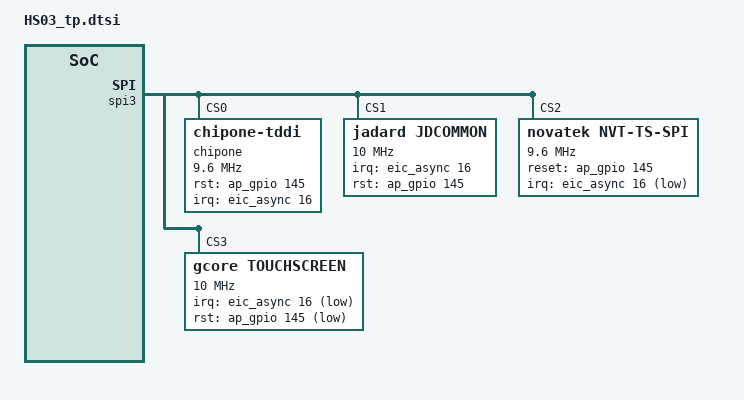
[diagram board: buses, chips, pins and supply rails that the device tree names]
&spi3 {
	status = "okay";
	cs-gpios = <0>, <0>, <0>, <0>;

	/*HS03 code for SR-SL6215-01-98|SR-SL6215-01-761|SR-SL6215-01-787  by zhoulingyun at 20211213 start*/
	/* chipone device tree node */
	chipone@0 {
		compatible = "chipone-tddi";
		reg = <0>; //Same as CS ID
		status = "ok";

		spi-max-frequency = <9600000>;	//4800000,9600000,15000000,19200000

		/*icnl9911c ===========start===========*/
		interrupt-parent = <&ap_gpio>;
		//interrupts = <144 0x2000>;
		chipone,rst-gpio = <&ap_gpio 145 GPIO_ACTIVE_HIGH>;
		/*HS03 code for P211028-04422  by chenyihong at 20211028 start*/
		chipone,irq-gpio = <&eic_async 16 GPIO_ACTIVE_HIGH>;
		/*HS03 code for P211028-04422  by chenyihong at 20211028 end*/
		touch,max-touch-number = <5>;
		touch,display-coords =  <0 0 720 1600>;
		chipone,x-res = <720>;
		chipone,y-res = <1600>;

		/* selftest settings */
		//selftest start
		chipone_hlt_hsd,test-reset-pin;
		//chipone_hlt_hsd,test-int-pin;
		chipone_hlt_hsd,test-rawdata;
		chipone_hlt_hsd,test-rawdata-frames = <1>;
		chipone_hlt_hsd,rawdata-min = <1430>;
		chipone_hlt_hsd,rawdata-max = <2970>;
		chipone_hlt_hsd,test-noise;
		chipone_hlt_hsd,test-noise-frames = <50>;
		chipone_hlt_hsd,noise-max = <76>;
		chipone_hlt_hsd,test-open;
		chipone_hlt_hsd,open-min = <3120>;
		chipone_hlt_hsd,test-short;
		chipone_hlt_hsd,short-min = <500>;
		chipone_hlt_hsd,test-compensate-cap;
		chipone_hlt_hsd,compensate-cap-min = <1>;
		chipone_hlt_hsd,compensate-cap-max = <126>;
		//selftest end

		/* selftest settings */
		//selftest start
		chipone_genrpro_inx,test-reset-pin;
		//chipone_genrpro_inx,test-int-pin;

		chipone_genrpro_inx,test-rawdata;
		chipone_genrpro_inx,test-rawdata-frames = <1>;
		chipone_genrpro_inx,rawdata-min = <1610>;//RAW_DEST_VALUE 2300*70%
		chipone_genrpro_inx,rawdata-max = <2990>;//RAW_DEST_VALUE 2300*130%

		chipone_genrpro_inx,test-noise;
		chipone_genrpro_inx,test-noise-frames = <50>;
		chipone_genrpro_inx,noise-max = <59>;//TCH_DOWN_TH_5PT 65*90% 

		chipone_genrpro_inx,test-open;
		chipone_genrpro_inx,open-min = <3466>;//SCAN_FREQ 97 /CYCLE_NUM 10 /SHIFT_NUM 7

		chipone_genrpro_inx,test-short;
		chipone_genrpro_inx,short-min = <500>;//default

		chipone_genrpro_inx,test-compensate-cap;
		chipone_genrpro_inx,compensate-cap-min = <1>;
		chipone_genrpro_inx,compensate-cap-max = <126>;
		//selftest end

		/* selftest settings */
		//selftest start
		chipone_tm,test-reset-pin;
		//chipone_tm,test-int-pin;

		chipone_tm,test-rawdata;
		chipone_tm,test-rawdata-frames = <1>;
		chipone_tm,rawdata-min = <1540>;
		chipone_tm,rawdata-max = <2860>;

		chipone_tm,test-noise;
		chipone_tm,test-noise-frames = <50>;
		chipone_tm,noise-max = <60>;

		chipone_tm,test-open;
		chipone_tm,open-min = <3100>;

		chipone_tm,test-short;
		chipone_tm,short-min = <500>;

		chipone_tm,test-compensate-cap;
		chipone_tm,compensate-cap-min = <1>;
		chipone_tm,compensate-cap-max = <126>;
		//selftest end

		/* selftest settings */
		//selftest start
		chipone_genrpro,test-reset-pin;
		//chipone_genrpro,test-int-pin;

		chipone_genrpro,test-rawdata;
		chipone_genrpro,test-rawdata-frames = <1>;
		chipone_genrpro,rawdata-min = <1610>;//base 2300*30%
		chipone_genrpro,rawdata-max = <2990>;

		chipone_genrpro,test-noise;
		chipone_genrpro,test-noise-frames = <50>;
		chipone_genrpro,noise-max = <70>;

		chipone_genrpro,test-open;
		chipone_genrpro,open-min = <3000>;

		chipone_genrpro,test-short;
		chipone_genrpro,short-min = <500>;

		chipone_genrpro,test-compensate-cap;
		chipone_genrpro,compensate-cap-min = <1>;
		chipone_genrpro,compensate-cap-max = <126>;
		//selftest end

		/* selftest settings */
		//selftest start
		chipone_truly_6mask,test-reset-pin;
		//chipone_truly_6mask,test-int-pin;

		chipone_truly_6mask,test-rawdata;
		chipone_truly_6mask,test-rawdata-frames = <1>;
		chipone_truly_6mask,rawdata-min = <1320>;//base 2200*40%
		chipone_truly_6mask,rawdata-max = <3080>;

		chipone_truly_6mask,test-noise;
		chipone_truly_6mask,test-noise-frames = <50>;
		chipone_truly_6mask,noise-max = <80>;

		chipone_truly_6mask,test-open;
		chipone_truly_6mask,open-min = <2700>;

		chipone_truly_6mask,test-short;
		chipone_truly_6mask,short-min = <500>;

		chipone_truly_6mask,test-compensate-cap;
		chipone_truly_6mask,compensate-cap-min = <1>;
		chipone_truly_6mask,compensate-cap-max = <126>;
		//selftest end

		/* selftest settings */
		//selftest start
		chipone_truly_7mask,test-reset-pin;
		//chipone_truly_7mask,test-int-pin;

		chipone_truly_7mask,test-rawdata;
		chipone_truly_7mask,test-rawdata-frames = <1>;
		chipone_truly_7mask,rawdata-min = <1320>;//base 2200*40%
		chipone_truly_7mask,rawdata-max = <3080>;

		chipone_truly_7mask,test-noise;
		chipone_truly_7mask,test-noise-frames = <50>;
		chipone_truly_7mask,noise-max = <80>;

		chipone_truly_7mask,test-open;
		chipone_truly_7mask,open-min = <2700>;

		chipone_truly_7mask,test-short;
		chipone_truly_7mask,short-min = <500>;

		chipone_truly_7mask,test-compensate-cap;
		chipone_truly_7mask,compensate-cap-min = <1>;
		chipone_truly_7mask,compensate-cap-max = <126>;
		//selftest end

		/* Charger detect */
		chipone,touch-charger-detect-enable;
		chipone,touch-charger-detect-type = "notify"; /* notify, poll */
		chipone,touch-charger-detect-psy-name = "usb";
		chipone,touch-charger-detect-psp = "POWER_SUPPLY_PROP_ONLINE";
		chipone,touch-charger-detect-psp-poll-interval = <1000>;

		/* Earjack detect */
		chipone,touch-earjack-detect-enable;
		/* MTK:  /sys/bus/platform/drivers/Accdet_Driver/state,
		Sprd: /sys/kernel/headset/state
		QCOM: None, and disable it */
		chipone,touch-earjack-state-filepath = "/sys/kernel/headset/state";
		chipone,touch-earjack-poll-interval = <1000>;
		/*icnl9911c ===========end===========*/
	};
	/*HS03 code for SR-SL6215-01-98|SR-SL6215-01-761|SR-SL6215-01-787  by zhoulingyun at 20211213 end*/

	/*HS03 code for SR-SL6215-01-108 by chenyihong at 20210729 start*/
	jadard@1 {
		compatible = "jadard,jdcommon";
		reg = <1>;
		spi-max-frequency = <10000000>;
		interrupt-parent = <&ap_gpio>;
		//interrupts = <144 0x2002>;
		jadard,panel-sense-nums = <18 32>;
		jadard,panel-coords = <0 720 0 1600>;
		jadard,panel-max-points = <10>;
		jadard,int-is-edge = <1>;
		/*HS03 code for P211028-04422  by chenyihong at 20211028 start*/
		jadard,irq-gpio = <&eic_async 16 GPIO_ACTIVE_HIGH>;
		/*HS03 code for P211028-04422  by chenyihong at 20211028 end*/
		jadard,rst-gpio = <&ap_gpio 145 GPIO_ACTIVE_HIGH>;
	};
	/*HS03 code for SR-SL6215-01-108 by chenyihong at 20210729 end*/

	/*HS03 code for SR-SL6215-01-102|SL6215DEV-3496 by zhoulingyun at 20211105 start*/
	/* Novatek device tree node */
	novatek@2 {
		compatible = "novatek,NVT-ts-spi";
		reg = <2>; //Same as CS ID
		status = "ok";

		interrupt-parent = <&ap_gpio>;
		//interrupts = <144 0x2001>;
		spi-max-frequency = <9600000>;	//4800000,9600000,15000000,19200000
		novatek,reset-gpio = <&ap_gpio 145 0x00>;
		/*HS03 code for P211028-04422  by chenyihong at 20211028 start*/
		novatek,irq-gpio = <&eic_async 16 0x2001>;
		/*HS03 code for P211028-04422  by chenyihong at 20211028 end*/

		/* 525 */
		//novatek,swrst-n8-addr = <0x01F01A>;

		/* 672A, 525B, 675, 526, 672C */
		novatek,swrst-n8-addr = <0x03F0FE>;
		novatek,spi-rd-fast-addr = <0x03F310>;

		/*Panel setting*/
		novatek,resolution = <720 1600>;
		novatek,max_touch_num = <10>;
		novatek,area-size = <56 112 60>;	//indicator navigation edge
		novatek,fw_name = "novatek_ts_fw.bin", "tsp_novatek/nt36525_a01core_tp.bin";
		novatek,fw_name_mp = "novatek_ts_mp.bin", "tsp_novatek/nt36525_a01core_mp.bin";
		novatek,support_ear_detect_mode;
		novatek,enable_settings_aot;

		/* MP */
		novatek,mp-support-dt;

		novatek-mp-criteria-7237@0 {
			#address-cells = <1>;
			#size-cells = <0>;
			compatible = "novatek-mp-criteria-7237";

			/* sec cmd test config */
			open_test_spec = <(-511) 5120>;
			short_test_spec = <10000 14008>;
			diff_test_frame = <50>;
			/* sec cmd fdm test config */
			fdm_x_num = <2>;
			fdm_diff_test_frame = <50>;

			/* MP Config */
			IC_X_CFG_SIZE = <18>;
			IC_Y_CFG_SIZE = <32>;
			IC_KEY_CFG_SIZE = <4>;
			X_Channel = <18>;
			Y_Channel = <32>;
			AIN_X = <0 1 2 3 4 5 6 7 8 9 10 11 12 13 14 15 16 17>;
			AIN_Y = <0 1 2 3 4 5 6 7 8 9 10 11 12 13 14 15 16 17
						18 19 20 21 22 23 24 25 26 27 28 29 30 31>;
			AIN_KEY = <0 1 2 0xFF>;
			/*HS03 code for SL6215DEV-189 by zhoulingyun at 20210818 start*/
			/* MP Criteria */
			PS_Config_Lmt_Short_Rawdata_P = <
				14008	14008	14008	14008	14008	14008	14008	14008	14008	14008	14008	14008	14008	14008	14008	14008	14008	14008
				14008	14008	14008	14008	14008	14008	14008	14008	14008	14008	14008	14008	14008	14008	14008	14008	14008	14008
				14008	14008	14008	14008	14008	14008	14008	14008	14008	14008	14008	14008	14008	14008	14008	14008	14008	14008
				14008	14008	14008	14008	14008	14008	14008	14008	14008	14008	14008	14008	14008	14008	14008	14008	14008	14008
				14008	14008	14008	14008	14008	14008	14008	14008	14008	14008	14008	14008	14008	14008	14008	14008	14008	14008
				14008	14008	14008	14008	14008	14008	14008	14008	14008	14008	14008	14008	14008	14008	14008	14008	14008	14008
				14008	14008	14008	14008	14008	14008	14008	14008	14008	14008	14008	14008	14008	14008	14008	14008	14008	14008
				14008	14008	14008	14008	14008	14008	14008	14008	14008	14008	14008	14008	14008	14008	14008	14008	14008	14008
				14008	14008	14008	14008	14008	14008	14008	14008	14008	14008	14008	14008	14008	14008	14008	14008	14008	14008
				14008	14008	14008	14008	14008	14008	14008	14008	14008	14008	14008	14008	14008	14008	14008	14008	14008	14008
				14008	14008	14008	14008	14008	14008	14008	14008	14008	14008	14008	14008	14008	14008	14008	14008	14008	14008
				14008	14008	14008	14008	14008	14008	14008	14008	14008	14008	14008	14008	14008	14008	14008	14008	14008	14008
				14008	14008	14008	14008	14008	14008	14008	14008	14008	14008	14008	14008	14008	14008	14008	14008	14008	14008
				14008	14008	14008	14008	14008	14008	14008	14008	14008	14008	14008	14008	14008	14008	14008	14008	14008	14008
				14008	14008	14008	14008	14008	14008	14008	14008	14008	14008	14008	14008	14008	14008	14008	14008	14008	14008
				14008	14008	14008	14008	14008	14008	14008	14008	14008	14008	14008	14008	14008	14008	14008	14008	14008	14008
				14008	14008	14008	14008	14008	14008	14008	14008	14008	14008	14008	14008	14008	14008	14008	14008	14008	14008
				14008	14008	14008	14008	14008	14008	14008	14008	14008	14008	14008	14008	14008	14008	14008	14008	14008	14008
				14008	14008	14008	14008	14008	14008	14008	14008	14008	14008	14008	14008	14008	14008	14008	14008	14008	14008
				14008	14008	14008	14008	14008	14008	14008	14008	14008	14008	14008	14008	14008	14008	14008	14008	14008	14008
				14008	14008	14008	14008	14008	14008	14008	14008	14008	14008	14008	14008	14008	14008	14008	14008	14008	14008
				14008	14008	14008	14008	14008	14008	14008	14008	14008	14008	14008	14008	14008	14008	14008	14008	14008	14008
				14008	14008	14008	14008	14008	14008	14008	14008	14008	14008	14008	14008	14008	14008	14008	14008	14008	14008
				14008	14008	14008	14008	14008	14008	14008	14008	14008	14008	14008	14008	14008	14008	14008	14008	14008	14008
				14008	14008	14008	14008	14008	14008	14008	14008	14008	14008	14008	14008	14008	14008	14008	14008	14008	14008
				14008	14008	14008	14008	14008	14008	14008	14008	14008	14008	14008	14008	14008	14008	14008	14008	14008	14008
				14008	14008	14008	14008	14008	14008	14008	14008	14008	14008	14008	14008	14008	14008	14008	14008	14008	14008
				14008	14008	14008	14008	14008	14008	14008	14008	14008	14008	14008	14008	14008	14008	14008	14008	14008	14008
				14008	14008	14008	14008	14008	14008	14008	14008	14008	14008	14008	14008	14008	14008	14008	14008	14008	14008
				14008	14008	14008	14008	14008	14008	14008	14008	14008	14008	14008	14008	14008	14008	14008	14008	14008	14008
				14008	14008	14008	14008	14008	14008	14008	14008	14008	14008	14008	14008	14008	14008	14008	14008	14008	14008
				14008	14008	14008	14008	14008	14008	14008	14008	14008	14008	14008	14008	14008	14008	14008	14008	14008	14008>;

			PS_Config_Lmt_Short_Rawdata_N = <
				11376	11376	11376	11376	11376	11376	11376	11376	11376	11376	11376	11376	11376	11376	11376	11376	11376	11376
				11376	11376	11376	11376	11376	11376	11376	11376	11376	11376	11376	11376	11376	11376	11376	11376	11376	11376
				11376	11376	11376	11376	11376	11376	11376	11376	11376	11376	11376	11376	11376	11376	11376	11376	11376	11376
				11376	11376	11376	11376	11376	11376	11376	11376	11376	11376	11376	11376	11376	11376	11376	11376	11376	11376
				11376	11376	11376	11376	11376	11376	11376	11376	11376	11376	11376	11376	11376	11376	11376	11376	11376	11376
				11376	11376	11376	11376	11376	11376	11376	11376	11376	11376	11376	11376	11376	11376	11376	11376	11376	11376
				11376	11376	11376	11376	11376	11376	11376	11376	11376	11376	11376	11376	11376	11376	11376	11376	11376	11376
				11376	11376	11376	11376	11376	11376	11376	11376	11376	11376	11376	11376	11376	11376	11376	11376	11376	11376
				11376	11376	11376	11376	11376	11376	11376	11376	11376	11376	11376	11376	11376	11376	11376	11376	11376	11376
				11376	11376	11376	11376	11376	11376	11376	11376	11376	11376	11376	11376	11376	11376	11376	11376	11376	11376
				11376	11376	11376	11376	11376	11376	11376	11376	11376	11376	11376	11376	11376	11376	11376	11376	11376	11376
				11376	11376	11376	11376	11376	11376	11376	11376	11376	11376	11376	11376	11376	11376	11376	11376	11376	11376
				11376	11376	11376	11376	11376	11376	11376	11376	11376	11376	11376	11376	11376	11376	11376	11376	11376	11376
				11376	11376	11376	11376	11376	11376	11376	11376	11376	11376	11376	11376	11376	11376	11376	11376	11376	11376
				11376	11376	11376	11376	11376	11376	11376	11376	11376	11376	11376	11376	11376	11376	11376	11376	11376	11376
				11376	11376	11376	11376	11376	11376	11376	11376	11376	11376	11376	11376	11376	11376	11376	11376	11376	11376
				11376	11376	11376	11376	11376	11376	11376	11376	11376	11376	11376	11376	11376	11376	11376	11376	11376	11376
				11376	11376	11376	11376	11376	11376	11376	11376	11376	11376	11376	11376	11376	11376	11376	11376	11376	11376
				11376	11376	11376	11376	11376	11376	11376	11376	11376	11376	11376	11376	11376	11376	11376	11376	11376	11376
				11376	11376	11376	11376	11376	11376	11376	11376	11376	11376	11376	11376	11376	11376	11376	11376	11376	11376
				11376	11376	11376	11376	11376	11376	11376	11376	11376	11376	11376	11376	11376	11376	11376	11376	11376	11376
				11376	11376	11376	11376	11376	11376	11376	11376	11376	11376	11376	11376	11376	11376	11376	11376	11376	11376
				11376	11376	11376	11376	11376	11376	11376	11376	11376	11376	11376	11376	11376	11376	11376	11376	11376	11376
				11376	11376	11376	11376	11376	11376	11376	11376	11376	11376	11376	11376	11376	11376	11376	11376	11376	11376
				11376	11376	11376	11376	11376	11376	11376	11376	11376	11376	11376	11376	11376	11376	11376	11376	11376	11376
				11376	11376	11376	11376	11376	11376	11376	11376	11376	11376	11376	11376	11376	11376	11376	11376	11376	11376
				11376	11376	11376	11376	11376	11376	11376	11376	11376	11376	11376	11376	11376	11376	11376	11376	11376	11376
				11376	11376	11376	11376	11376	11376	11376	11376	11376	11376	11376	11376	11376	11376	11376	11376	11376	11376
				11376	11376	11376	11376	11376	11376	11376	11376	11376	11376	11376	11376	11376	11376	11376	11376	11376	11376
				11376	11376	11376	11376	11376	11376	11376	11376	11376	11376	11376	11376	11376	11376	11376	11376	11376	11376
				11376	11376	11376	11376	11376	11376	11376	11376	11376	11376	11376	11376	11376	11376	11376	11376	11376	11376
				11376	11376	11376	11376	11376	11376	11376	11376	11376	11376	11376	11376	11376	11376	11376	11376	11376	11376>;

			PS_Config_Lmt_Open_Rawdata_P = <
				3112	3123	3131	3166	3204	3169	3148	3222	3222	3211	3211	3140	3171	3213	3257	3308	3318	3255
				2907	2920	2963	3033	3099	3092	3080	3067	3018	2994	3057	3070	3095	3102	3117	3134	3101	3035
				2989	3005	3047	3123	3199	3196	3172	3165	3105	2994	3054	3073	3092	3105	3117	3140	3108	3056
				2997	3001	3047	3122	3201	3203	3180	3171	3110	3029	3098	3115	3137	3148	3162	3183	3158	3116
				3026	3035	3081	3158	3238	3232	3210	3200	3138	3033	3103	3122	3140	3155	3166	3186	3169	3127
				3011	3017	3061	3138	3218	3234	3211	3201	3133	3102	3179	3194	3215	3235	3246	3266	3253	3207
				3140	3151	3182	3193	3193	3183	3192	3175	3143	3270	3288	3311	3299	3290	3199	3105	3039	2989
				3140	3148	3180	3197	3190	3190	3186	3178	3140	3264	3287	3301	3304	3304	3222	3119	3053	3003
				3175	3189	3227	3249	3239	3232	3220	3213	3176	3330	3357	3371	3385	3386	3302	3197	3134	3084
				3214	3232	3281	3299	3298	3298	3287	3269	3232	3392	3418	3442	3449	3456	3367	3263	3197	3140
				3273	3287	3337	3354	3340	3330	3316	3299	3271	3372	3396	3420	3432	3446	3374	3269	3203	3148
				3311	3329	3388	3407	3402	3392	3369	3351	3325	3463	3488	3509	3536	3549	3476	3368	3299	3243
				3313	3329	3417	3428	3425	3414	3396	3381	3364	3427	3449	3465	3493	3505	3435	3336	3248	3190
				3337	3358	3439	3463	3448	3444	3423	3407	3388	3480	3502	3518	3543	3556	3504	3402	3315	3253
				3389	3413	3490	3508	3497	3479	3470	3459	3431	3528	3554	3572	3582	3610	3554	3466	3378	3318
				3452	3472	3546	3572	3549	3537	3511	3498	3467	3600	3628	3647	3665	3683	3644	3551	3463	3399
				3462	3476	3550	3568	3558	3550	3529	3514	3484	3560	3585	3605	3631	3649	3612	3533	3444	3378
				3529	3553	3624	3645	3637	3626	3603	3589	3557	3609	3638	3665	3684	3704	3672	3599	3512	3449
				3561	3574	3647	3651	3649	3637	3620	3596	3565	3637	3673	3696	3724	3739	3714	3644	3565	3494
				3607	3628	3701	3721	3717	3703	3689	3669	3638	3665	3703	3721	3745	3763	3749	3677	3605	3540
				3628	3633	3698	3725	3712	3700	3682	3659	3623	3704	3742	3763	3789	3806	3798	3722	3656	3598
				3701	3710	3782	3817	3809	3801	3784	3761	3722	3725	3767	3791	3816	3833	3838	3768	3693	3633
				3774	3778	3833	3901	3901	3887	3862	3843	3798	3778	3826	3847	3873	3889	3911	3873	3815	3756
				3801	3799	3852	3913	3917	3904	3880	3858	3815	3805	3852	3876	3901	3915	3936	3915	3857	3805
				3822	3819	3871	3929	3945	3934	3918	3896	3850	3757	3805	3822	3845	3858	3875	3865	3809	3771
				3851	3841	3887	3939	3955	3945	3924	3903	3858	3872	3917	3936	3960	3976	3994	3990	3938	3900
				3691	3885	3925	3980	3998	3988	3992	3974	3935	3873	3917	3935	3935	3957	3971	3969	3928	3683
				3696	3890	3931	3969	3990	3981	3985	3969	3929	3922	3969	3987	3988	4009	4022	4034	3995	3731
				3750	3956	3992	4033	4054	4047	4044	4034	3991	3896	3943	3957	3963	3981	3998	4012	3978	3718
				3732	3936	3974	4004	4029	4025	4023	4009	3967	4013	4058	4071	4076	4090	4111	4138	4104	3824
				3799	4016	4048	4072	4096	4088	4089	4072	4033	3932	3974	3988	3994	4011	4026	4060	4036	3766
				3869	3936	4051	4069	4095	4088	4089	4071	4030	3998	4043	4053	4060	4076	4097	4131	4019	3897>;

			PS_Config_Lmt_Open_Rawdata_N = <
				1333	1338	1342	1357	1373	1358	1349	1381	1381	1376	1376	1345	1359	1377	1396	1417	1422	1395
				1246	1251	1270	1300	1328	1325	1320	1314	1293	1283	1310	1315	1326	1329	1336	1343	1329	1300
				1281	1288	1306	1338	1371	1369	1359	1356	1330	1283	1309	1317	1325	1330	1336	1345	1332	1309
				1284	1286	1306	1338	1372	1372	1363	1359	1333	1298	1327	1335	1344	1349	1355	1364	1353	1335
				1297	1300	1320	1353	1387	1385	1375	1371	1345	1300	1330	1338	1345	1352	1357	1365	1358	1340
				1290	1293	1312	1345	1379	1386	1376	1372	1342	1329	1362	1369	1378	1386	1391	1399	1394	1374
				1345	1350	1363	1368	1368	1364	1368	1360	1347	1401	1409	1419	1414	1410	1371	1330	1302	1281
				1345	1349	1363	1370	1367	1367	1365	1362	1345	1399	1408	1414	1416	1416	1381	1336	1308	1287
				1360	1366	1383	1392	1388	1385	1380	1377	1361	1427	1438	1444	1450	1451	1415	1370	1343	1321
				1377	1385	1406	1414	1413	1413	1408	1401	1385	1453	1465	1475	1478	1481	1443	1398	1370	1345
				1402	1408	1430	1437	1431	1427	1421	1414	1402	1445	1455	1465	1471	1477	1446	1401	1372	1349
				1419	1426	1452	1460	1458	1453	1444	1436	1425	1484	1495	1504	1515	1521	1489	1443	1414	1390
				1420	1426	1464	1469	1468	1463	1455	1449	1441	1468	1478	1485	1497	1502	1472	1429	1392	1367
				1430	1439	1474	1484	1477	1476	1467	1460	1452	1491	1501	1507	1518	1524	1501	1458	1420	1394
				1452	1462	1495	1503	1498	1491	1487	1482	1470	1512	1523	1531	1535	1547	1523	1485	1447	1422
				1479	1488	1519	1531	1521	1516	1504	1499	1486	1543	1555	1563	1570	1578	1561	1522	1484	1456
				1483	1489	1521	1529	1525	1521	1512	1506	1493	1525	1536	1545	1556	1564	1548	1514	1476	1447
				1512	1522	1553	1562	1558	1554	1544	1538	1524	1546	1559	1570	1579	1587	1573	1542	1505	1478
				1526	1531	1563	1564	1564	1558	1551	1541	1528	1558	1574	1584	1596	1602	1591	1561	1528	1497
				1546	1555	1586	1594	1593	1587	1581	1572	1559	1570	1587	1594	1605	1612	1606	1576	1545	1517
				1555	1557	1585	1596	1591	1585	1578	1568	1552	1587	1603	1612	1624	1631	1627	1595	1567	1542
				1586	1590	1621	1636	1632	1629	1621	1612	1595	1596	1614	1624	1635	1642	1645	1615	1582	1557
				1617	1619	1642	1672	1672	1666	1655	1647	1627	1619	1639	1648	1660	1666	1676	1660	1635	1609
				1629	1628	1651	1677	1678	1673	1663	1653	1635	1630	1651	1661	1672	1678	1687	1678	1653	1630
				1638	1636	1659	1684	1690	1686	1679	1669	1650	1610	1630	1638	1648	1653	1660	1656	1632	1616
				1650	1646	1666	1688	1695	1690	1681	1672	1653	1659	1678	1687	1697	1704	1711	1710	1687	1671
				1582	1665	1682	1705	1713	1709	1711	1703	1686	1660	1678	1686	1686	1696	1702	1701	1683	1578
				1584	1667	1684	1701	1710	1706	1708	1701	1684	1681	1701	1708	1709	1718	1723	1729	1712	1599
				1607	1695	1711	1728	1737	1734	1733	1729	1710	1669	1690	1696	1698	1706	1713	1719	1705	1593
				1599	1687	1703	1716	1726	1725	1724	1718	1700	1720	1739	1744	1747	1753	1762	1773	1759	1639
				1628	1721	1735	1745	1755	1752	1752	1745	1728	1685	1703	1709	1711	1719	1725	1740	1729	1614
				1658	1687	1736	1744	1755	1752	1752	1744	1727	1713	1732	1737	1740	1747	1756	1770	1722	1670>;

			PS_Config_Lmt_FW_Rawdata_P = <
				3386	3360	3285	3389	3319	3313	3404	3395	3395	3414	3414	3395	3453	3326	3270	3281	3326	3386
				3291	3315	3319	3329	3410	3360	3414	3434	3431	3390	3392	3413	3402	3389	3434	3393	3411	3463
				3421	3358	3399	3451	3381	3438	3329	3330	3340	3313	3330	3320	3344	3319	3309	3388	3403	3336
				3357	3291	3410	3318	3393	3388	3395	3341	3311	3264	3274	3259	3288	3204	3246	3339	3488	3260
				3383	3340	3350	3379	3242	3319	3246	3325	3346	3288	3344	3304	3318	3246	3270	3348	3424	3318
				3292	3444	3420	3353	3250	3264	3243	3332	3297	3416	3403	3402	3421	3381	3399	3444	3332	3421
				3350	3318	3379	3332	3381	3382	3348	3298	3365	3459	3383	3372	3355	3348	3361	3407	3319	3393
				3351	3249	3361	3273	3319	3339	3284	3281	3340	3421	3404	3392	3372	3379	3414	3301	3368	3323
				3326	3368	3327	3353	3381	3322	3365	3385	3347	3238	3248	3232	3232	3312	3386	3425	3395	3343
				3397	3369	3329	3369	3320	3295	3358	3402	3369	3358	3407	3414	3382	3357	3350	3339	3393	3340
				3297	3395	3411	3425	3453	3417	3479	3378	3497	3423	3400	3411	3392	3369	3326	3348	3312	3379
				3333	3332	3428	3379	3399	3378	3413	3315	3325	3390	3382	3354	3365	3304	3325	3348	3357	3409
				3382	3407	3386	3420	3346	3360	3360	3385	3393	3229	3299	3299	3290	3280	3329	3404	3402	3297
				3295	3456	3421	3474	3375	3402	3423	3465	3446	3323	3274	3294	3270	3333	3323	3424	3245	3362
				3378	3330	3348	3376	3367	3383	3357	3361	3348	3347	3353	3341	3365	3386	3432	3371	3416	3374
				3330	3444	3427	3379	3383	3421	3368	3329	3351	3357	3397	3392	3397	3285	3236	3304	3262	3386
				3449	3214	3274	3225	3260	3302	3277	3285	3250	3299	3329	3332	3336	3290	3403	3390	3414	3416
				3395	3294	3257	3288	3322	3313	3326	3277	3311	3413	3374	3375	3386	3348	3383	3445	3406	3353
				3382	3395	3399	3404	3393	3365	3428	3375	3439	3374	3452	3452	3420	3442	3431	3351	3381	3341
				3381	3285	3259	3304	3270	3346	3269	3308	3315	3382	3333	3322	3308	3332	3346	3438	3410	3344
				3403	3362	3379	3347	3326	3318	3334	3353	3383	3358	3281	3285	3294	3250	3222	3304	3262	3320
				3312	3474	3431	3437	3463	3451	3465	3502	3472	3392	3399	3414	3381	3336	3372	3298	3375	3263
				3378	3388	3327	3199	3351	3395	3397	3203	3381	3375	3299	3278	3306	3273	3281	3238	3333	3283
				3393	3382	3392	3402	3362	3367	3371	3409	3396	3269	3360	3368	3389	3292	3333	3329	3423	3350
				3382	3337	3467	3383	3418	3444	3402	3400	3413	3305	3339	3340	3355	3276	3304	3305	3414	3325
				3404	3409	3343	3413	3386	3365	3365	3406	3400	3273	3334	3320	3330	3271	3267	3292	3375	3360
				3529	3480	3410	3458	3438	3416	3421	3427	3434	3270	3358	3336	3351	3284	3302	3341	3456	3409
				3375	3353	3453	3322	3375	3390	3420	3361	3414	3374	3423	3407	3360	3395	3392	3295	3346	3423
				3388	3420	3299	3333	3305	3250	3292	3375	3383	3375	3434	3437	3448	3397	3430	3444	3351	3386
				3416	3418	3306	3319	3253	3232	3270	3302	3347	3353	3406	3404	3410	3444	3449	3491	3346	3332
				3390	3400	3295	3290	3276	3297	3264	3332	3383	3442	3420	3423	3420	3403	3423	3462	3313	3277
				3386	3346	3362	3350	3346	3341	3372	3388	3446	3381	3287	3259	3257	3353	3318	3295	3344	3386>;

			PS_Config_Lmt_FW_Rawdata_N = <
				1451	1440	1408	1452	1422	1420	1459	1455	1455	1463	1463	1455	1480	1425	1401	1406	1425	1451
				1410	1420	1422	1426	1461	1440	1463	1471	1470	1453	1453	1462	1458	1452	1471	1454	1462	1484
				1466	1439	1456	1479	1449	1473	1426	1427	1431	1420	1427	1423	1433	1422	1418	1452	1458	1429
				1438	1410	1461	1422	1454	1452	1455	1432	1419	1399	1403	1396	1409	1373	1391	1431	1495	1397
				1450	1431	1435	1448	1389	1422	1391	1425	1434	1409	1433	1416	1422	1391	1401	1435	1467	1422
				1411	1476	1465	1437	1393	1399	1390	1428	1413	1464	1458	1458	1466	1449	1456	1476	1428	1466
				1435	1422	1448	1428	1449	1449	1435	1413	1442	1482	1450	1445	1438	1435	1440	1460	1422	1454
				1436	1392	1440	1402	1422	1431	1407	1406	1431	1466	1459	1453	1445	1448	1463	1414	1443	1424
				1425	1443	1426	1437	1449	1423	1442	1450	1434	1387	1392	1385	1385	1419	1451	1468	1455	1432
				1456	1444	1426	1444	1423	1412	1439	1458	1444	1439	1460	1463	1449	1438	1435	1431	1454	1431
				1413	1455	1462	1468	1480	1464	1491	1447	1498	1467	1457	1462	1453	1444	1425	1435	1419	1448
				1428	1428	1469	1448	1456	1447	1462	1420	1425	1453	1449	1437	1442	1416	1425	1435	1438	1461
				1449	1460	1451	1465	1434	1440	1440	1450	1454	1384	1414	1414	1410	1405	1426	1459	1458	1413
				1412	1481	1466	1489	1446	1458	1467	1485	1477	1424	1403	1411	1401	1428	1424	1467	1390	1441
				1447	1427	1435	1447	1443	1450	1438	1440	1435	1434	1437	1432	1442	1451	1471	1444	1464	1446
				1427	1476	1468	1448	1450	1466	1443	1426	1436	1438	1456	1453	1456	1408	1387	1416	1398	1451
				1478	1377	1403	1382	1397	1415	1404	1408	1393	1414	1426	1428	1429	1410	1458	1453	1463	1464
				1455	1411	1396	1409	1423	1420	1425	1404	1419	1462	1446	1446	1451	1435	1450	1476	1459	1437
				1449	1455	1456	1459	1454	1442	1469	1446	1474	1446	1479	1479	1465	1475	1470	1436	1449	1432
				1449	1408	1396	1416	1401	1434	1401	1417	1420	1449	1428	1423	1417	1428	1434	1473	1461	1433
				1458	1441	1448	1434	1425	1422	1429	1437	1450	1439	1406	1408	1411	1393	1381	1416	1398	1423
				1419	1489	1470	1473	1484	1479	1485	1501	1488	1453	1456	1463	1449	1429	1445	1413	1446	1398
				1447	1452	1426	1371	1436	1455	1456	1372	1449	1446	1414	1405	1417	1402	1406	1387	1428	1407
				1454	1449	1453	1458	1441	1443	1444	1461	1455	1401	1440	1443	1452	1411	1428	1426	1467	1435
				1449	1430	1486	1450	1465	1476	1458	1457	1462	1416	1431	1431	1438	1404	1416	1416	1463	1425
				1459	1461	1432	1462	1451	1442	1442	1459	1457	1402	1429	1423	1427	1402	1400	1411	1446	1440
				1512	1491	1461	1482	1473	1464	1466	1468	1471	1401	1439	1429	1436	1407	1415	1432	1481	1461
				1446	1437	1480	1423	1446	1453	1465	1440	1463	1446	1467	1460	1440	1455	1453	1412	1434	1467
				1452	1465	1414	1428	1416	1393	1411	1446	1450	1446	1471	1473	1477	1456	1470	1476	1436	1451
				1464	1465	1417	1422	1394	1385	1401	1415	1434	1437	1459	1459	1461	1476	1478	1496	1434	1428
				1453	1457	1412	1410	1404	1413	1399	1428	1450	1475	1465	1467	1465	1458	1467	1483	1420	1404
				1451	1434	1441	1435	1434	1432	1445	1452	1477	1449	1408	1396	1396	1437	1422	1412	1433	1451>;

			PS_Config_Lmt_FW_CC_P = <
				89	88	88	89	89	89	91	91	91	97	97	97	96	96	96	96	96	96
				95	92	92	92	92	93	92	92	95	97	96	96	96	96	96	96	96	97
				95	93	93	93	95	95	95	95	97	99	97	97	97	96	96	97	97	99
				95	95	95	95	95	95	95	95	97	100	97	97	97	97	97	97	97	100
				95	93	92	93	95	95	95	95	97	99	96	96	96	96	96	96	96	99
				97	95	95	95	96	96	96	96	100	99	96	96	96	96	96	96	97	99
				97	95	95	95	95	95	95	95	97	103	100	100	100	100	99	97	99	100
				100	99	97	99	99	97	99	99	102	104	102	102	102	100	100	100	100	102
				97	95	95	95	95	95	95	95	97	103	100	100	100	99	97	97	97	100
				100	99	99	99	99	99	99	99	102	106	103	103	103	103	103	102	102	103
				99	97	96	96	96	96	96	96	99	103	100	100	100	100	100	99	99	100
				102	100	99	100	99	99	99	100	102	104	102	102	102	102	100	100	100	103
				97	95	95	96	95	95	95	96	97	104	102	102	102	100	100	99	99	102
				99	97	96	96	96	96	96	96	99	107	104	104	104	103	103	103	103	104
				99	97	97	97	96	96	97	97	100	104	102	102	102	102	100	100	100	102
				102	100	100	100	100	99	100	100	103	106	103	103	103	103	103	102	102	103
				99	97	97	97	97	97	97	97	100	100	97	97	97	97	97	97	97	99
				100	97	97	97	97	97	97	97	100	107	104	106	106	104	104	103	104	106
				96	95	93	93	93	93	93	93	96	102	99	99	99	99	99	99	99	100
				102	100	99	100	99	99	99	100	102	109	106	106	106	104	104	104	104	107
				99	96	96	96	96	96	96	96	99	104	103	103	103	102	103	102	103	104
				106	103	103	103	103	103	103	103	106	104	102	103	103	102	102	102	102	104
				100	99	99	99	99	99	99	99	102	104	102	102	102	102	102	102	102	104
				97	95	95	95	95	95	95	95	97	102	99	99	99	99	99	99	100	102
				100	97	97	97	97	97	97	97	100	103	100	100	100	100	100	100	100	103
				102	100	100	100	100	100	100	100	103	104	102	102	102	102	102	102	103	104
				97	96	96	96	96	96	96	96	99	102	99	99	99	99	99	99	100	100
				99	99	97	97	97	97	97	97	100	104	102	102	102	100	100	102	102	102
				100	100	100	100	100	100	100	100	102	104	102	102	102	100	102	102	103	102
				97	97	97	97	97	97	97	97	100	104	102	102	102	102	102	102	103	103
				97	97	96	96	96	96	96	96	99	102	99	99	97	97	97	97	100	100
				96	96	96	96	96	96	96	96	99	106	103	103	103	102	102	102	102	103>;

			PS_Config_Lmt_FW_CC_N = <
				40	39	39	40	40	40	40	40	40	44	44	44	43	43	43	43	43	43
				42	41	41	41	41	42	41	41	42	44	43	43	43	43	43	43	43	44
				42	42	42	42	42	42	42	42	44	44	44	44	44	43	43	44	44	44
				42	42	42	42	42	42	42	42	44	45	44	44	44	44	44	44	44	45
				42	42	41	42	42	42	42	42	44	44	43	43	43	43	43	43	43	44
				44	42	42	42	43	43	43	43	45	44	43	43	43	43	43	43	44	44
				44	42	42	42	42	42	42	42	44	46	45	45	45	45	44	44	44	45
				45	44	44	44	44	44	44	44	45	47	45	45	45	45	45	45	45	45
				44	42	42	42	42	42	42	42	44	46	45	45	45	44	44	44	44	45
				45	44	44	44	44	44	44	44	45	47	46	46	46	46	46	45	45	46
				44	44	43	43	43	43	43	43	44	46	45	45	45	45	45	44	44	45
				45	45	44	45	44	44	44	45	45	47	45	45	45	45	45	45	45	46
				44	42	42	43	42	42	42	43	44	47	45	45	45	45	45	44	44	45
				44	44	43	43	43	43	43	43	44	48	47	47	47	46	46	46	46	47
				44	44	44	44	43	43	44	44	45	47	45	45	45	45	45	45	45	45
				45	45	45	45	45	44	45	45	46	47	46	46	46	46	46	45	45	46
				44	44	44	44	44	44	44	44	45	45	44	44	44	44	44	44	44	44
				45	44	44	44	44	44	44	44	45	48	47	47	47	47	47	46	47	47
				43	42	42	42	42	42	42	42	43	45	44	44	44	44	44	44	44	45
				45	45	44	45	44	44	44	45	45	48	47	47	47	47	47	47	47	48
				44	43	43	43	43	43	43	43	44	47	46	46	46	45	46	45	46	47
				47	46	46	46	46	46	46	46	47	47	45	46	46	45	45	45	45	47
				45	44	44	44	44	44	44	44	45	47	45	45	45	45	45	45	45	47
				44	42	42	42	42	42	42	42	44	45	44	44	44	44	44	44	45	45
				45	44	44	44	44	44	44	44	45	46	45	45	45	45	45	45	45	46
				45	45	45	45	45	45	45	45	46	47	45	45	45	45	45	45	46	47
				44	43	43	43	43	43	43	43	44	45	44	44	44	44	44	44	45	45
				44	44	44	44	44	44	44	44	45	47	45	45	45	45	45	45	45	45
				45	45	45	45	45	45	45	45	45	47	45	45	45	45	45	45	46	45
				44	44	44	44	44	44	44	44	45	47	45	45	45	45	45	45	46	46
				44	44	43	43	43	43	43	43	44	45	44	44	44	44	44	44	45	45
				43	43	43	43	43	43	43	43	44	47	46	46	46	45	45	45	45	46>;

			PS_Config_Lmt_FW_Diff_P = <
				50	50	50	50	50	50	50	50	50	50	50	50	50	50	50	50	50	50
				50	50	50	50	50	50	50	50	50	50	50	50	50	50	50	50	50	50
				50	50	50	50	50	50	50	50	50	50	50	50	50	50	50	50	50	50
				50	50	50	50	50	50	50	50	50	50	50	50	50	50	50	50	50	50
				50	50	50	50	50	50	50	50	50	50	50	50	50	50	50	50	50	50
				50	50	50	50	50	50	50	50	50	50	50	50	50	50	50	50	50	50
				50	50	50	50	50	50	50	50	50	50	50	50	50	50	50	50	50	50
				50	50	50	50	50	50	50	50	50	50	50	50	50	50	50	50	50	50
				50	50	50	50	50	50	50	50	50	50	50	50	50	50	50	50	50	50
				50	50	50	50	50	50	50	50	50	50	50	50	50	50	50	50	50	50
				50	50	50	50	50	50	50	50	50	50	50	50	50	50	50	50	50	50
				50	50	50	50	50	50	50	50	50	50	50	50	50	50	50	50	50	50
				50	50	50	50	50	50	50	50	50	50	50	50	50	50	50	50	50	50
				50	50	50	50	50	50	50	50	50	50	50	50	50	50	50	50	50	50
				50	50	50	50	50	50	50	50	50	50	50	50	50	50	50	50	50	50
				50	50	50	50	50	50	50	50	50	50	50	50	50	50	50	50	50	50
				50	50	50	50	50	50	50	50	50	50	50	50	50	50	50	50	50	50
				50	50	50	50	50	50	50	50	50	50	50	50	50	50	50	50	50	50
				50	50	50	50	50	50	50	50	50	50	50	50	50	50	50	50	50	50
				50	50	50	50	50	50	50	50	50	50	50	50	50	50	50	50	50	50
				50	50	50	50	50	50	50	50	50	50	50	50	50	50	50	50	50	50
				50	50	50	50	50	50	50	50	50	50	50	50	50	50	50	50	50	50
				50	50	50	50	50	50	50	50	50	50	50	50	50	50	50	50	50	50
				50	50	50	50	50	50	50	50	50	50	50	50	50	50	50	50	50	50
				50	50	50	50	50	50	50	50	50	50	50	50	50	50	50	50	50	50
				50	50	50	50	50	50	50	50	50	50	50	50	50	50	50	50	50	50
				50	50	50	50	50	50	50	50	50	50	50	50	50	50	50	50	50	50
				50	50	50	50	50	50	50	50	50	50	50	50	50	50	50	50	50	50
				50	50	50	50	50	50	50	50	50	50	50	50	50	50	50	50	50	50
				50	50	50	50	50	50	50	50	50	50	50	50	50	50	50	50	50	50
				50	50	50	50	50	50	50	50	50	50	50	50	50	50	50	50	50	50
				50	50	50	50	50	50	50	50	50	50	50	50	50	50	50	50	50	50>;

			PS_Config_Lmt_FW_Diff_N = <
				(-50)	(-50)	(-50)	(-50)	(-50)	(-50)	(-50)	(-50)	(-50)	(-50)	(-50)	(-50)	(-50)	(-50)	(-50)	(-50)	(-50)	(-50)
				(-50)	(-50)	(-50)	(-50)	(-50)	(-50)	(-50)	(-50)	(-50)	(-50)	(-50)	(-50)	(-50)	(-50)	(-50)	(-50)	(-50)	(-50)
				(-50)	(-50)	(-50)	(-50)	(-50)	(-50)	(-50)	(-50)	(-50)	(-50)	(-50)	(-50)	(-50)	(-50)	(-50)	(-50)	(-50)	(-50)
				(-50)	(-50)	(-50)	(-50)	(-50)	(-50)	(-50)	(-50)	(-50)	(-50)	(-50)	(-50)	(-50)	(-50)	(-50)	(-50)	(-50)	(-50)
				(-50)	(-50)	(-50)	(-50)	(-50)	(-50)	(-50)	(-50)	(-50)	(-50)	(-50)	(-50)	(-50)	(-50)	(-50)	(-50)	(-50)	(-50)
				(-50)	(-50)	(-50)	(-50)	(-50)	(-50)	(-50)	(-50)	(-50)	(-50)	(-50)	(-50)	(-50)	(-50)	(-50)	(-50)	(-50)	(-50)
				(-50)	(-50)	(-50)	(-50)	(-50)	(-50)	(-50)	(-50)	(-50)	(-50)	(-50)	(-50)	(-50)	(-50)	(-50)	(-50)	(-50)	(-50)
				(-50)	(-50)	(-50)	(-50)	(-50)	(-50)	(-50)	(-50)	(-50)	(-50)	(-50)	(-50)	(-50)	(-50)	(-50)	(-50)	(-50)	(-50)
				(-50)	(-50)	(-50)	(-50)	(-50)	(-50)	(-50)	(-50)	(-50)	(-50)	(-50)	(-50)	(-50)	(-50)	(-50)	(-50)	(-50)	(-50)
				(-50)	(-50)	(-50)	(-50)	(-50)	(-50)	(-50)	(-50)	(-50)	(-50)	(-50)	(-50)	(-50)	(-50)	(-50)	(-50)	(-50)	(-50)
				(-50)	(-50)	(-50)	(-50)	(-50)	(-50)	(-50)	(-50)	(-50)	(-50)	(-50)	(-50)	(-50)	(-50)	(-50)	(-50)	(-50)	(-50)
				(-50)	(-50)	(-50)	(-50)	(-50)	(-50)	(-50)	(-50)	(-50)	(-50)	(-50)	(-50)	(-50)	(-50)	(-50)	(-50)	(-50)	(-50)
				(-50)	(-50)	(-50)	(-50)	(-50)	(-50)	(-50)	(-50)	(-50)	(-50)	(-50)	(-50)	(-50)	(-50)	(-50)	(-50)	(-50)	(-50)
				(-50)	(-50)	(-50)	(-50)	(-50)	(-50)	(-50)	(-50)	(-50)	(-50)	(-50)	(-50)	(-50)	(-50)	(-50)	(-50)	(-50)	(-50)
				(-50)	(-50)	(-50)	(-50)	(-50)	(-50)	(-50)	(-50)	(-50)	(-50)	(-50)	(-50)	(-50)	(-50)	(-50)	(-50)	(-50)	(-50)
				(-50)	(-50)	(-50)	(-50)	(-50)	(-50)	(-50)	(-50)	(-50)	(-50)	(-50)	(-50)	(-50)	(-50)	(-50)	(-50)	(-50)	(-50)
				(-50)	(-50)	(-50)	(-50)	(-50)	(-50)	(-50)	(-50)	(-50)	(-50)	(-50)	(-50)	(-50)	(-50)	(-50)	(-50)	(-50)	(-50)
				(-50)	(-50)	(-50)	(-50)	(-50)	(-50)	(-50)	(-50)	(-50)	(-50)	(-50)	(-50)	(-50)	(-50)	(-50)	(-50)	(-50)	(-50)
				(-50)	(-50)	(-50)	(-50)	(-50)	(-50)	(-50)	(-50)	(-50)	(-50)	(-50)	(-50)	(-50)	(-50)	(-50)	(-50)	(-50)	(-50)
				(-50)	(-50)	(-50)	(-50)	(-50)	(-50)	(-50)	(-50)	(-50)	(-50)	(-50)	(-50)	(-50)	(-50)	(-50)	(-50)	(-50)	(-50)
				(-50)	(-50)	(-50)	(-50)	(-50)	(-50)	(-50)	(-50)	(-50)	(-50)	(-50)	(-50)	(-50)	(-50)	(-50)	(-50)	(-50)	(-50)
				(-50)	(-50)	(-50)	(-50)	(-50)	(-50)	(-50)	(-50)	(-50)	(-50)	(-50)	(-50)	(-50)	(-50)	(-50)	(-50)	(-50)	(-50)
				(-50)	(-50)	(-50)	(-50)	(-50)	(-50)	(-50)	(-50)	(-50)	(-50)	(-50)	(-50)	(-50)	(-50)	(-50)	(-50)	(-50)	(-50)
				(-50)	(-50)	(-50)	(-50)	(-50)	(-50)	(-50)	(-50)	(-50)	(-50)	(-50)	(-50)	(-50)	(-50)	(-50)	(-50)	(-50)	(-50)
				(-50)	(-50)	(-50)	(-50)	(-50)	(-50)	(-50)	(-50)	(-50)	(-50)	(-50)	(-50)	(-50)	(-50)	(-50)	(-50)	(-50)	(-50)
				(-50)	(-50)	(-50)	(-50)	(-50)	(-50)	(-50)	(-50)	(-50)	(-50)	(-50)	(-50)	(-50)	(-50)	(-50)	(-50)	(-50)	(-50)
				(-50)	(-50)	(-50)	(-50)	(-50)	(-50)	(-50)	(-50)	(-50)	(-50)	(-50)	(-50)	(-50)	(-50)	(-50)	(-50)	(-50)	(-50)
				(-50)	(-50)	(-50)	(-50)	(-50)	(-50)	(-50)	(-50)	(-50)	(-50)	(-50)	(-50)	(-50)	(-50)	(-50)	(-50)	(-50)	(-50)
				(-50)	(-50)	(-50)	(-50)	(-50)	(-50)	(-50)	(-50)	(-50)	(-50)	(-50)	(-50)	(-50)	(-50)	(-50)	(-50)	(-50)	(-50)
				(-50)	(-50)	(-50)	(-50)	(-50)	(-50)	(-50)	(-50)	(-50)	(-50)	(-50)	(-50)	(-50)	(-50)	(-50)	(-50)	(-50)	(-50)
				(-50)	(-50)	(-50)	(-50)	(-50)	(-50)	(-50)	(-50)	(-50)	(-50)	(-50)	(-50)	(-50)	(-50)	(-50)	(-50)	(-50)	(-50)
				(-50)	(-50)	(-50)	(-50)	(-50)	(-50)	(-50)	(-50)	(-50)	(-50)	(-50)	(-50)	(-50)	(-50)	(-50)	(-50)	(-50)	(-50)>;

			PS_Config_Diff_Test_Frame = <50>;
			/*HS03 code for SL6215DEV-189 by zhoulingyun at 20210818 end*/

			PS_Config_Lmt_LPWG_Rawdata_P = <
				3000 3000 3000 3000 3000 3000 3000 3000 3000 3000 3000 3000 3000 3000 3000 3000 3000 3000
				3000 3000 3000 3000 3000 3000 3000 3000 3000 3000 3000 3000 3000 3000 3000 3000 3000 3000
				3000 3000 3000 3000 3000 3000 3000 3000 3000 3000 3000 3000 3000 3000 3000 3000 3000 3000
				3000 3000 3000 3000 3000 3000 3000 3000 3000 3000 3000 3000 3000 3000 3000 3000 3000 3000
				3000 3000 3000 3000 3000 3000 3000 3000 3000 3000 3000 3000 3000 3000 3000 3000 3000 3000
				3000 3000 3000 3000 3000 3000 3000 3000 3000 3000 3000 3000 3000 3000 3000 3000 3000 3000
				3000 3000 3000 3000 3000 3000 3000 3000 3000 3000 3000 3000 3000 3000 3000 3000 3000 3000
				3000 3000 3000 3000 3000 3000 3000 3000 3000 3000 3000 3000 3000 3000 3000 3000 3000 3000
				3000 3000 3000 3000 3000 3000 3000 3000 3000 3000 3000 3000 3000 3000 3000 3000 3000 3000
				3000 3000 3000 3000 3000 3000 3000 3000 3000 3000 3000 3000 3000 3000 3000 3000 3000 3000
				3000 3000 3000 3000 3000 3000 3000 3000 3000 3000 3000 3000 3000 3000 3000 3000 3000 3000
				3000 3000 3000 3000 3000 3000 3000 3000 3000 3000 3000 3000 3000 3000 3000 3000 3000 3000
				3000 3000 3000 3000 3000 3000 3000 3000 3000 3000 3000 3000 3000 3000 3000 3000 3000 3000
				3000 3000 3000 3000 3000 3000 3000 3000 3000 3000 3000 3000 3000 3000 3000 3000 3000 3000
				3000 3000 3000 3000 3000 3000 3000 3000 3000 3000 3000 3000 3000 3000 3000 3000 3000 3000
				3000 3000 3000 3000 3000 3000 3000 3000 3000 3000 3000 3000 3000 3000 3000 3000 3000 3000
				3000 3000 3000 3000 3000 3000 3000 3000 3000 3000 3000 3000 3000 3000 3000 3000 3000 3000
				3000 3000 3000 3000 3000 3000 3000 3000 3000 3000 3000 3000 3000 3000 3000 3000 3000 3000
				3000 3000 3000 3000 3000 3000 3000 3000 3000 3000 3000 3000 3000 3000 3000 3000 3000 3000
				3000 3000 3000 3000 3000 3000 3000 3000 3000 3000 3000 3000 3000 3000 3000 3000 3000 3000
				3000 3000 3000 3000 3000 3000 3000 3000 3000 3000 3000 3000 3000 3000 3000 3000 3000 3000
				3000 3000 3000 3000 3000 3000 3000 3000 3000 3000 3000 3000 3000 3000 3000 3000 3000 3000
				3000 3000 3000 3000 3000 3000 3000 3000 3000 3000 3000 3000 3000 3000 3000 3000 3000 3000
				3000 3000 3000 3000 3000 3000 3000 3000 3000 3000 3000 3000 3000 3000 3000 3000 3000 3000
				3000 3000 3000 3000 3000 3000 3000 3000 3000 3000 3000 3000 3000 3000 3000 3000 3000 3000
				3000 3000 3000 3000 3000 3000 3000 3000 3000 3000 3000 3000 3000 3000 3000 3000 3000 3000
				3000 3000 3000 3000 3000 3000 3000 3000 3000 3000 3000 3000 3000 3000 3000 3000 3000 3000
				3000 3000 3000 3000 3000 3000 3000 3000 3000 3000 3000 3000 3000 3000 3000 3000 3000 3000
				3000 3000 3000 3000 3000 3000 3000 3000 3000 3000 3000 3000 3000 3000 3000 3000 3000 3000
				3000 3000 3000 3000 3000 3000 3000 3000 3000 3000 3000 3000 3000 3000 3000 3000 3000 3000
				3000 3000 3000 3000 3000 3000 3000 3000 3000 3000 3000 3000 3000 3000 3000 3000 3000 3000
				3000 3000 3000 3000 3000 3000 3000 3000 3000 3000 3000 3000 3000 3000 3000 3000 3000 3000
				3000 3000 3000>;

			PS_Config_Lmt_LPWG_Rawdata_N = <
				240 240 240 240 240 240 240 240 240 240 240 240 240 240 240 240 240 240
				240 240 240 240 240 240 240 240 240 240 240 240 240 240 240 240 240 240
				240 240 240 240 240 240 240 240 240 240 240 240 240 240 240 240 240 240
				240 240 240 240 240 240 240 240 240 240 240 240 240 240 240 240 240 240
				240 240 240 240 240 240 240 240 240 240 240 240 240 240 240 240 240 240
				240 240 240 240 240 240 240 240 240 240 240 240 240 240 240 240 240 240
				240 240 240 240 240 240 240 240 240 240 240 240 240 240 240 240 240 240
				240 240 240 240 240 240 240 240 240 240 240 240 240 240 240 240 240 240
				240 240 240 240 240 240 240 240 240 240 240 240 240 240 240 240 240 240
				240 240 240 240 240 240 240 240 240 240 240 240 240 240 240 240 240 240
				240 240 240 240 240 240 240 240 240 240 240 240 240 240 240 240 240 240
				240 240 240 240 240 240 240 240 240 240 240 240 240 240 240 240 240 240
				240 240 240 240 240 240 240 240 240 240 240 240 240 240 240 240 240 240
				240 240 240 240 240 240 240 240 240 240 240 240 240 240 240 240 240 240
				240 240 240 240 240 240 240 240 240 240 240 240 240 240 240 240 240 240
				240 240 240 240 240 240 240 240 240 240 240 240 240 240 240 240 240 240
				240 240 240 240 240 240 240 240 240 240 240 240 240 240 240 240 240 240
				240 240 240 240 240 240 240 240 240 240 240 240 240 240 240 240 240 240
				240 240 240 240 240 240 240 240 240 240 240 240 240 240 240 240 240 240
				240 240 240 240 240 240 240 240 240 240 240 240 240 240 240 240 240 240
				240 240 240 240 240 240 240 240 240 240 240 240 240 240 240 240 240 240
				240 240 240 240 240 240 240 240 240 240 240 240 240 240 240 240 240 240
				240 240 240 240 240 240 240 240 240 240 240 240 240 240 240 240 240 240
				240 240 240 240 240 240 240 240 240 240 240 240 240 240 240 240 240 240
				240 240 240 240 240 240 240 240 240 240 240 240 240 240 240 240 240 240
				240 240 240 240 240 240 240 240 240 240 240 240 240 240 240 240 240 240
				240 240 240 240 240 240 240 240 240 240 240 240 240 240 240 240 240 240
				240 240 240 240 240 240 240 240 240 240 240 240 240 240 240 240 240 240
				240 240 240 240 240 240 240 240 240 240 240 240 240 240 240 240 240 240
				240 240 240 240 240 240 240 240 240 240 240 240 240 240 240 240 240 240
				240 240 240 240 240 240 240 240 240 240 240 240 240 240 240 240 240 240
				240 240 240 240 240 240 240 240 240 240 240 240 240 240 240 240 240 240
				240 240 240>;

			PS_Config_Lmt_LPWG_Diff_P = <
				75 75 75 75 75 75 75 75 75 75 75 75 75 75 75 75 75 75
				75 75 75 75 75 75 75 75 75 75 75 75 75 75 75 75 75 75
				75 75 75 75 75 75 75 75 75 75 75 75 75 75 75 75 75 75
				75 75 75 75 75 75 75 75 75 75 75 75 75 75 75 75 75 75
				75 75 75 75 75 75 75 75 75 75 75 75 75 75 75 75 75 75
				75 75 75 75 75 75 75 75 75 75 75 75 75 75 75 75 75 75
				75 75 75 75 75 75 75 75 75 75 75 75 75 75 75 75 75 75
				75 75 75 75 75 75 75 75 75 75 75 75 75 75 75 75 75 75
				75 75 75 75 75 75 75 75 75 75 75 75 75 75 75 75 75 75
				75 75 75 75 75 75 75 75 75 75 75 75 75 75 75 75 75 75
				75 75 75 75 75 75 75 75 75 75 75 75 75 75 75 75 75 75
				75 75 75 75 75 75 75 75 75 75 75 75 75 75 75 75 75 75
				75 75 75 75 75 75 75 75 75 75 75 75 75 75 75 75 75 75
				75 75 75 75 75 75 75 75 75 75 75 75 75 75 75 75 75 75
				75 75 75 75 75 75 75 75 75 75 75 75 75 75 75 75 75 75
				75 75 75 75 75 75 75 75 75 75 75 75 75 75 75 75 75 75
				75 75 75 75 75 75 75 75 75 75 75 75 75 75 75 75 75 75
				75 75 75 75 75 75 75 75 75 75 75 75 75 75 75 75 75 75
				75 75 75 75 75 75 75 75 75 75 75 75 75 75 75 75 75 75
				75 75 75 75 75 75 75 75 75 75 75 75 75 75 75 75 75 75
				75 75 75 75 75 75 75 75 75 75 75 75 75 75 75 75 75 75
				75 75 75 75 75 75 75 75 75 75 75 75 75 75 75 75 75 75
				75 75 75 75 75 75 75 75 75 75 75 75 75 75 75 75 75 75
				75 75 75 75 75 75 75 75 75 75 75 75 75 75 75 75 75 75
				75 75 75 75 75 75 75 75 75 75 75 75 75 75 75 75 75 75
				75 75 75 75 75 75 75 75 75 75 75 75 75 75 75 75 75 75
				75 75 75 75 75 75 75 75 75 75 75 75 75 75 75 75 75 75
				75 75 75 75 75 75 75 75 75 75 75 75 75 75 75 75 75 75
				75 75 75 75 75 75 75 75 75 75 75 75 75 75 75 75 75 75
				75 75 75 75 75 75 75 75 75 75 75 75 75 75 75 75 75 75
				75 75 75 75 75 75 75 75 75 75 75 75 75 75 75 75 75 75
				75 75 75 75 75 75 75 75 75 75 75 75 75 75 75 75 75 75
				75 75 75>;

			PS_Config_Lmt_LPWG_Diff_N = <
				(-75) (-75) (-75) (-75) (-75) (-75) (-75) (-75) (-75) (-75) (-75) (-75) (-75) (-75) (-75) (-75) (-75) (-75)
				(-75) (-75) (-75) (-75) (-75) (-75) (-75) (-75) (-75) (-75) (-75) (-75) (-75) (-75) (-75) (-75) (-75) (-75)
				(-75) (-75) (-75) (-75) (-75) (-75) (-75) (-75) (-75) (-75) (-75) (-75) (-75) (-75) (-75) (-75) (-75) (-75)
				(-75) (-75) (-75) (-75) (-75) (-75) (-75) (-75) (-75) (-75) (-75) (-75) (-75) (-75) (-75) (-75) (-75) (-75)
				(-75) (-75) (-75) (-75) (-75) (-75) (-75) (-75) (-75) (-75) (-75) (-75) (-75) (-75) (-75) (-75) (-75) (-75)
				(-75) (-75) (-75) (-75) (-75) (-75) (-75) (-75) (-75) (-75) (-75) (-75) (-75) (-75) (-75) (-75) (-75) (-75)
				(-75) (-75) (-75) (-75) (-75) (-75) (-75) (-75) (-75) (-75) (-75) (-75) (-75) (-75) (-75) (-75) (-75) (-75)
				(-75) (-75) (-75) (-75) (-75) (-75) (-75) (-75) (-75) (-75) (-75) (-75) (-75) (-75) (-75) (-75) (-75) (-75)
				(-75) (-75) (-75) (-75) (-75) (-75) (-75) (-75) (-75) (-75) (-75) (-75) (-75) (-75) (-75) (-75) (-75) (-75)
				(-75) (-75) (-75) (-75) (-75) (-75) (-75) (-75) (-75) (-75) (-75) (-75) (-75) (-75) (-75) (-75) (-75) (-75)
				(-75) (-75) (-75) (-75) (-75) (-75) (-75) (-75) (-75) (-75) (-75) (-75) (-75) (-75) (-75) (-75) (-75) (-75)
				(-75) (-75) (-75) (-75) (-75) (-75) (-75) (-75) (-75) (-75) (-75) (-75) (-75) (-75) (-75) (-75) (-75) (-75)
				(-75) (-75) (-75) (-75) (-75) (-75) (-75) (-75) (-75) (-75) (-75) (-75) (-75) (-75) (-75) (-75) (-75) (-75)
				(-75) (-75) (-75) (-75) (-75) (-75) (-75) (-75) (-75) (-75) (-75) (-75) (-75) (-75) (-75) (-75) (-75) (-75)
				(-75) (-75) (-75) (-75) (-75) (-75) (-75) (-75) (-75) (-75) (-75) (-75) (-75) (-75) (-75) (-75) (-75) (-75)
				(-75) (-75) (-75) (-75) (-75) (-75) (-75) (-75) (-75) (-75) (-75) (-75) (-75) (-75) (-75) (-75) (-75) (-75)
				(-75) (-75) (-75) (-75) (-75) (-75) (-75) (-75) (-75) (-75) (-75) (-75) (-75) (-75) (-75) (-75) (-75) (-75)
				(-75) (-75) (-75) (-75) (-75) (-75) (-75) (-75) (-75) (-75) (-75) (-75) (-75) (-75) (-75) (-75) (-75) (-75)
				(-75) (-75) (-75) (-75) (-75) (-75) (-75) (-75) (-75) (-75) (-75) (-75) (-75) (-75) (-75) (-75) (-75) (-75)
				(-75) (-75) (-75) (-75) (-75) (-75) (-75) (-75) (-75) (-75) (-75) (-75) (-75) (-75) (-75) (-75) (-75) (-75)
				(-75) (-75) (-75) (-75) (-75) (-75) (-75) (-75) (-75) (-75) (-75) (-75) (-75) (-75) (-75) (-75) (-75) (-75)
				(-75) (-75) (-75) (-75) (-75) (-75) (-75) (-75) (-75) (-75) (-75) (-75) (-75) (-75) (-75) (-75) (-75) (-75)
				(-75) (-75) (-75) (-75) (-75) (-75) (-75) (-75) (-75) (-75) (-75) (-75) (-75) (-75) (-75) (-75) (-75) (-75)
				(-75) (-75) (-75) (-75) (-75) (-75) (-75) (-75) (-75) (-75) (-75) (-75) (-75) (-75) (-75) (-75) (-75) (-75)
				(-75) (-75) (-75) (-75) (-75) (-75) (-75) (-75) (-75) (-75) (-75) (-75) (-75) (-75) (-75) (-75) (-75) (-75)
				(-75) (-75) (-75) (-75) (-75) (-75) (-75) (-75) (-75) (-75) (-75) (-75) (-75) (-75) (-75) (-75) (-75) (-75)
				(-75) (-75) (-75) (-75) (-75) (-75) (-75) (-75) (-75) (-75) (-75) (-75) (-75) (-75) (-75) (-75) (-75) (-75)
				(-75) (-75) (-75) (-75) (-75) (-75) (-75) (-75) (-75) (-75) (-75) (-75) (-75) (-75) (-75) (-75) (-75) (-75)
				(-75) (-75) (-75) (-75) (-75) (-75) (-75) (-75) (-75) (-75) (-75) (-75) (-75) (-75) (-75) (-75) (-75) (-75)
				(-75) (-75) (-75) (-75) (-75) (-75) (-75) (-75) (-75) (-75) (-75) (-75) (-75) (-75) (-75) (-75) (-75) (-75)
				(-75) (-75) (-75) (-75) (-75) (-75) (-75) (-75) (-75) (-75) (-75) (-75) (-75) (-75) (-75) (-75) (-75) (-75)
				(-75) (-75) (-75) (-75) (-75) (-75) (-75) (-75) (-75) (-75) (-75) (-75) (-75) (-75) (-75) (-75) (-75) (-75)
				(-75) (-75) (-75)>;

			/* FDM config */
			FDM_X_Channel = <2>;

			PS_Config_Lmt_FDM_Rawdata_P = <
				900 900
				900 900
				900 900
				900 900
				900 900
				900 900
				900 900
				900 900
				900 900
				900 900
				900 900
				900 900
				900 900
				900 900
				900 900
				900 900
				900 900
				900 900
				900 900
				900 900
				900 900
				900 900
				900 900
				900 900
				900 900
				900 900
				900 900
				900 900
				900 900
				900 900
				900 900
				900 900
				900 900
				900 900
				900 900
				900 900>;

			PS_Config_Lmt_FDM_Rawdata_N = <
				50 50
				50 50
				50 50
				50 50
				50 50
				50 50
				50 50
				50 50
				50 50
				50 50
				50 50
				50 50
				50 50
				50 50
				50 50
				50 50
				50 50
				50 50
				50 50
				50 50
				50 50
				50 50
				50 50
				50 50
				50 50
				50 50
				50 50
				50 50
				50 50
				50 50
				50 50
				50 50
				50 50
				50 50
				50 50
				50 50>;

			PS_Config_FDM_Noise_Test_Frame = <50>;
			PS_Config_Lmt_FDM_Diff_P = <
				180 180
				180 180
				180 180
				180 180
				180 180
				180 180
				180 180
				180 180
				180 180
				180 180
				180 180
				180 180
				180 180
				180 180
				180 180
				180 180
				180 180
				180 180
				180 180
				180 180
				180 180
				180 180
				180 180
				180 180
				180 180
				180 180
				180 180
				180 180
				180 180
				180 180
				180 180
				180 180
				180 180
				180 180
				180 180
				180 180>;

			PS_Config_Lmt_FDM_Diff_N = <
				(-180) (-180)
				(-180) (-180)
				(-180) (-180)
				(-180) (-180)
				(-180) (-180)
				(-180) (-180)
				(-180) (-180)
				(-180) (-180)
				(-180) (-180)
				(-180) (-180)
				(-180) (-180)
				(-180) (-180)
				(-180) (-180)
				(-180) (-180)
				(-180) (-180)
				(-180) (-180)
				(-180) (-180)
				(-180) (-180)
				(-180) (-180)
				(-180) (-180)
				(-180) (-180)
				(-180) (-180)
				(-180) (-180)
				(-180) (-180)
				(-180) (-180)
				(-180) (-180)
				(-180) (-180)
				(-180) (-180)
				(-180) (-180)
				(-180) (-180)
				(-180) (-180)
				(-180) (-180)
				(-180) (-180)
				(-180) (-180)
				(-180) (-180)
				(-180) (-180)>;
		};
	};
	/*HS03 code for SR-SL6215-01-102|SL6215DEV-3496 by zhoulingyun at 20211105 end*/

	/*HS03 code for SR-SL6215-01-90 by wangjianqiu at 20210810 start*/
	gcore@3 {
		compatible = "gcore,touchscreen";
		reg = <3>;
		spi-max-frequency = <10000000>;
		interrupt-parent = <&ap_gpio>;
		//interrupts = <144 0x2002>;
		/*HS03 code for P211028-04422  by chenyihong at 20211028 start*/
		gcore,irq-gpio = <&eic_async 16 GPIO_ACTIVE_LOW>;
		/*HS03 code for P211028-04422  by chenyihong at 20211028 end*/
		gcore,rst-gpio = <&ap_gpio 145 GPIO_ACTIVE_LOW>;
	};
	/*HS03 code for SR-SL6215-01-90 by wangjianqiu at 20210810 end*/
};
